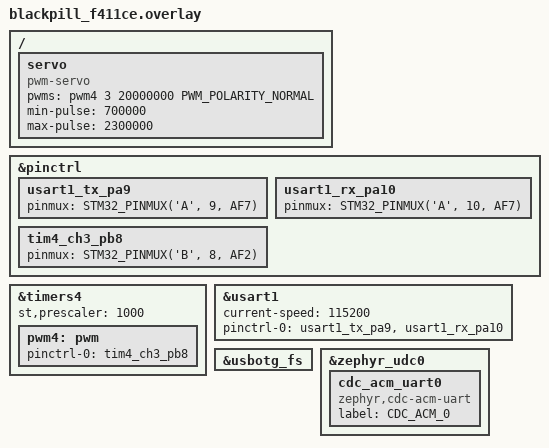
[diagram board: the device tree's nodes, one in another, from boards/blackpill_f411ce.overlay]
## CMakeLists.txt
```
cmake_minimum_required(VERSION 3.20.0)
find_package(Zephyr REQUIRED HINTS $ENV{ZEPHYR_BASE})
project(gripper)

target_sources(app PRIVATE src/main.c)
```

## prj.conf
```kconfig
# Gripper servo motor control for STM32F411 Black Pill
# Based on zephyr/samples/basic/servo_motor with overlay from joint_microros_tmc2209_gripper

CONFIG_GPIO=y

CONFIG_PWM=y
CONFIG_PWM_STM32=y
#CONFIG_PWM_SERVO=y

# USB CDC ACM configuration (console via USB)
CONFIG_USB_DEVICE_STACK=y
CONFIG_USB_DEVICE_PRODUCT="STM32 CDC"
CONFIG_USB_DEVICE_VID=0x0483
CONFIG_USB_DEVICE_PID=0x5740
CONFIG_USB_CDC_ACM=y
CONFIG_USB_CDC_ACM_RINGBUF_SIZE=256

# Console
CONFIG_SERIAL=y
CONFIG_UART_INTERRUPT_DRIVEN=y
CONFIG_UART_LINE_CTRL=y
CONFIG_CONSOLE=y
CONFIG_UART_CONSOLE=y
CONFIG_PRINTK=y
CONFIG_STDOUT_CONSOLE=y

# Auto-initialize USB at boot
CONFIG_USB_DEVICE_INITIALIZE_AT_BOOT=y
```

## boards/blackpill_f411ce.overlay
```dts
/* Blackpill F411 - Servo on PB6 (TIM4 Channel 1) */

#include <zephyr/dt-bindings/pwm/pwm.h>


/* ==================== PWM Configuration ==================== */

&pinctrl {
    usart1_tx_pa9: usart1_tx_pa9 {
        pinmux = <STM32_PINMUX('A', 9, AF7)>;
    };
    usart1_rx_pa10: usart1_rx_pa10 {
        pinmux = <STM32_PINMUX('A', 10, AF7)>;
    };
    /* PB8 as TIM4 Channel 3 */
    tim4_ch3_pb8: tim4_ch3_pb8 {
        pinmux = <STM32_PINMUX('B', 8, AF2)>;
    };
};

&timers4 {
    status = "okay";
    st,prescaler = <1000>; // Helpt om binnen het bereik van de timer te blijven

    pwm4: pwm {
        status = "okay";
        pinctrl-0 = <&tim4_ch3_pb8>;
        pinctrl-names = "default";
    };
};

/ {
    servo: servo {
        compatible = "pwm-servo";
        pwms = <&pwm4 3 20000000 PWM_POLARITY_NORMAL>;
        min-pulse = <700000>;   // 0.7ms
        max-pulse = <2300000>;  // 2.3ms
    };
};




/* USART1 (PA9/PA10) for serial debug output */
&usart1 {
    status = "okay";
    current-speed = <115200>;
    pinctrl-0 = <&usart1_tx_pa9 &usart1_rx_pa10>;
    pinctrl-names = "default";
};


/* Enable USB CDC for console/shell */
&usbotg_fs {
    status = "okay";
};

&zephyr_udc0 {
    cdc_acm_uart0: cdc_acm_uart0 {
        compatible = "zephyr,cdc-acm-uart";
        label = "CDC_ACM_0";
    };
};
```

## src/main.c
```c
#include <zephyr/kernel.h>
#include <zephyr/sys/printk.h>
#include <zephyr/device.h>
#include <zephyr/drivers/pwm.h>
#include <zephyr/drivers/uart.h>
#include <zephyr/drivers/uart/cdc_acm.h>

static const struct pwm_dt_spec servo = PWM_DT_SPEC_GET(DT_NODELABEL(servo));
static const uint32_t min_pulse = DT_PROP(DT_NODELABEL(servo), min_pulse);
static const uint32_t max_pulse = DT_PROP(DT_NODELABEL(servo), max_pulse);

static const struct device *cdc_acm_dev;

static void uart_print(const struct device *dev, const char *str)
{
    if (!dev || !device_is_ready(dev)) {
        return;
    }
    for (int i = 0; str[i] != '\0'; i++) {
        uart_poll_out(dev, str[i]);
    }
}

#define STEP PWM_USEC(100)

enum direction {
	DOWN,
	UP,
};

int main(void)
{
	uint32_t pulse_width = min_pulse;
       // uint32_t pulse_width = 700000; 
	enum direction dir = UP;
	int ret;

	cdc_acm_dev = DEVICE_DT_GET(DT_NODELABEL(cdc_acm_uart0));

	if (!device_is_ready(cdc_acm_dev)) {
		printk("CDC ACM device not ready\n");
		return 0;
	}

	uart_print(cdc_acm_dev, "Gripper servo control (USB CDC)\r\n");

	printk("Gripper servo control\n");

	if (!pwm_is_ready_dt(&servo)) {
		printk("Error: PWM device %s is not ready\n", servo.dev->name);
		uart_print(cdc_acm_dev, "Error: PWM device not ready\r\n");
		return 0;
	}

	while (1) {
		ret = pwm_set_pulse_dt(&servo, pulse_width);
		if (ret < 0) {
			printk("Error %d: failed to set pulse width\n", ret);
			uart_print(cdc_acm_dev, "Error: failed to set pulse width\r\n");
			return 0;
		}

		printk("Pulse width: %d us\n", pulse_width);
		{
			char buf[64];
			int n = snprintf(buf, sizeof(buf), "Pulse width: %d us\r\n", pulse_width);
			if (n > 0) {
				uart_print(cdc_acm_dev, buf);
			}
		}

		if (dir == DOWN) {
			if (pulse_width <= min_pulse) {
				dir = UP;
				pulse_width = min_pulse;
			} else {
				pulse_width -= STEP;
			}
		} else {
			pulse_width += STEP;
			if (pulse_width >= max_pulse) {
				dir = DOWN;
				pulse_width = max_pulse;
			}
		}
		k_sleep(K_SECONDS(1));
	}
	return 0;
}
```
